# ESP32S31_RADIO register map
Vendor: Espressif; Series: ESP32-S31; File version: 3.52
Registers are 32-bit, read-write, no defined reset value unless marked. A register's access mark holds for its fields unless they carry their own. Offsets are from the block's base; [hi:lo] are bit positions; {n}, {i} and the like mark numbered series; 'fields as' and 'values as' point back to an identical list.

## WIFI_MAC_TXRX_CALLBACKS — Hardware effects of the three HE callbacks between the direct mac_txrx_init prefix and suffix. Diagnostic logging calls are intentionally omitted.
Base 0x2010444C
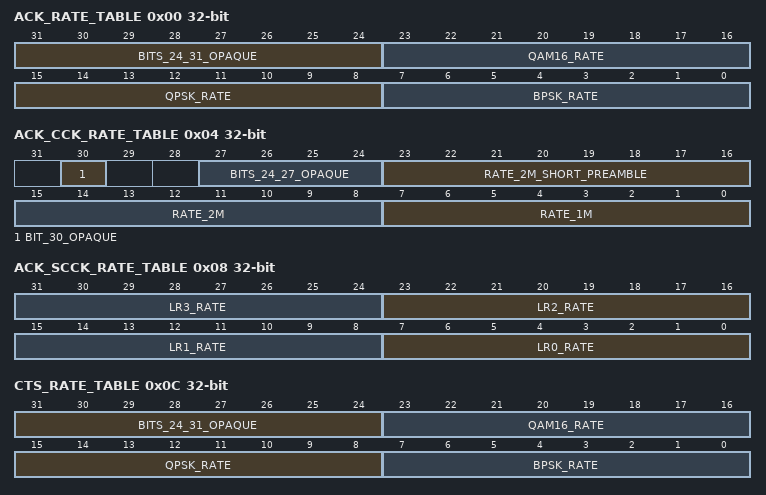
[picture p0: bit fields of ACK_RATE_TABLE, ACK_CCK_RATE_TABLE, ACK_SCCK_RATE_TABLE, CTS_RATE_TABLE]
0x00 ACK_RATE_TABLE — Project-assigned name. ACK_TAB0. hal_he_set_ack_rate(0) publishes 0x00090a0b; complete dbg_read_ack_rate names its three byte lanes.
  [31:24] BITS_24_31_OPAQUE — Opaque: meaning not established.
  [23:16] QAM16_RATE — Project-assigned name.
  [15:8] QPSK_RATE — Project-assigned name.
  [7:0] BPSK_RATE — Project-assigned name.
0x04 ACK_CCK_RATE_TABLE — Project-assigned name. ACK_TAB1. hal_he_set_ack_rate(0) publishes 0x00050100; complete dbg_read_ack_rate names the 1M, 2M and short-preamble 2M lanes.
  [30] BIT_30_OPAQUE — Opaque: meaning not established. Observed source use; the individual hardware meaning is unknown.
  [27:24] BITS_24_27_OPAQUE — Opaque: meaning not established. Observed source use; the individual hardware meaning is unknown.
  [23:16] RATE_2M_SHORT_PREAMBLE — Project-assigned name.
  [15:8] RATE_2M — Project-assigned name.
  [7:0] RATE_1M — Project-assigned name.
0x08 ACK_SCCK_RATE_TABLE — Project-assigned name. ACK_SCCKTAB, decoded by complete dbg_read_ack_rate. The cold setter does not alter this word.
  [8n+7:8n] LR{n}_RATE (n=0..3) — Project-assigned name.
0x0C CTS_RATE_TABLE — Project-assigned name. CTS_TAB0. hal_he_set_ack_rate(0) publishes 0x00090a0b; complete dbg_read_cts_rate names its three byte lanes.
  fields as ACK_RATE_TABLE
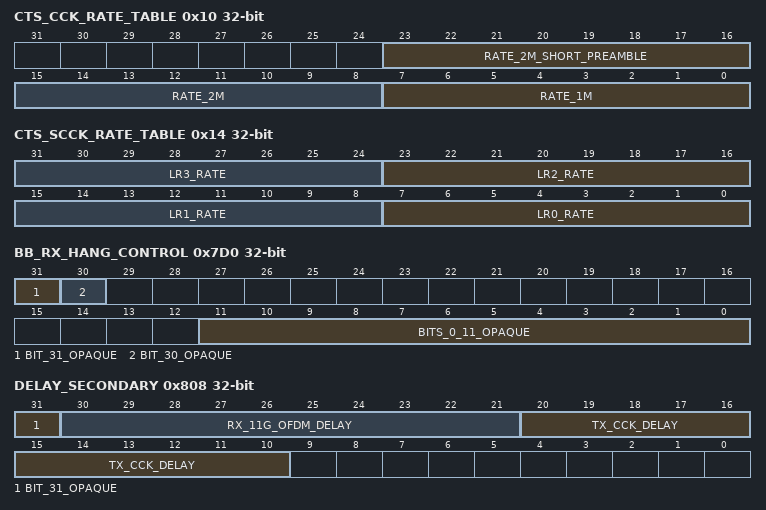
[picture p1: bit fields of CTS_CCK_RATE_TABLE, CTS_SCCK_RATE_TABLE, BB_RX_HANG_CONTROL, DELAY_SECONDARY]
0x10 CTS_CCK_RATE_TABLE — Project-assigned name. CTS_TAB1. hal_he_set_ack_rate(0) publishes 0x00050100; complete dbg_read_cts_rate names the 1M, 2M and short-preamble 2M lanes.
  [23:16] RATE_2M_SHORT_PREAMBLE — Project-assigned name.
  [15:8] RATE_2M — Project-assigned name.
  [7:0] RATE_1M — Project-assigned name.
0x14 CTS_SCCK_RATE_TABLE — Project-assigned name. CTS_SCCKTAB, decoded by complete dbg_read_cts_rate. The cold setter does not alter this word.
  [8n+7:8n] LR{n}_RATE (n=0..3) — Project-assigned name.
0x7D0 BB_RX_HANG_CONTROL — Project-assigned name. Canonical multifunction word. hal_he_set_bbrxhung_time(0) replaces the low twelve bits with 0x00f; the direct mac_txrx_init suffix later sets bits 31 and 30 through two fresh-read RMWs.
  [31] BIT_31_OPAQUE — Opaque: meaning not established.
  [30] BIT_30_OPAQUE — Opaque: meaning not established.
  [11:0] BITS_0_11_OPAQUE — Opaque: meaning not established.
0x808 DELAY_SECONDARY — Project-assigned name. WDEVDELAY1. On-chip hal_he_set_mac_delay uses random slot 0..10 for WDEV_RX_11G_OFDM_DELAY, while complete phy_sifs_reg_init writes 0xea to that field.
  [31] BIT_31_OPAQUE — Opaque: meaning not established. Observed source use; the individual hardware meaning is unknown.
  [30:21] RX_11G_OFDM_DELAY — Project-assigned name.
  [20:10] TX_CCK_DELAY — Project-assigned name.
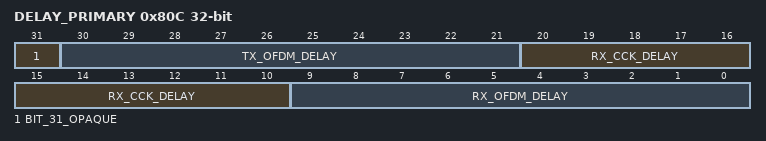
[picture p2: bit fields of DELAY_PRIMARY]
0x80C DELAY_PRIMARY — Project-assigned name. WDEVDELAY. On-chip hal_he_set_mac_delay performs separate RMWs for WDEV_RXCCK_DELAY, WDEV_RXOFDM_DELAY and WDEV_TXOFDM_DELAY; complete phy_sifs_reg_init writes 0x3b8 and 0xf0 to the first two fields.
  [31] BIT_31_OPAQUE — Opaque: meaning not established. Observed source use; the individual hardware meaning is unknown.
  [30:21] TX_OFDM_DELAY — Project-assigned name.
  [20:10] RX_CCK_DELAY — Project-assigned name.
  [9:0] RX_OFDM_DELAY — Project-assigned name.

## WIFI_MAC_TXRX_SUFFIX — Eight Wi-Fi-owned direct fresh-read RMW edges after the three external HE callbacks in complete mac_txrx_init. The ninth edge reaches the independently shared physical word at 0x20104C24 and is modeled by SHARED_RADIO_INIT_CONTROL.
Base 0x20104308
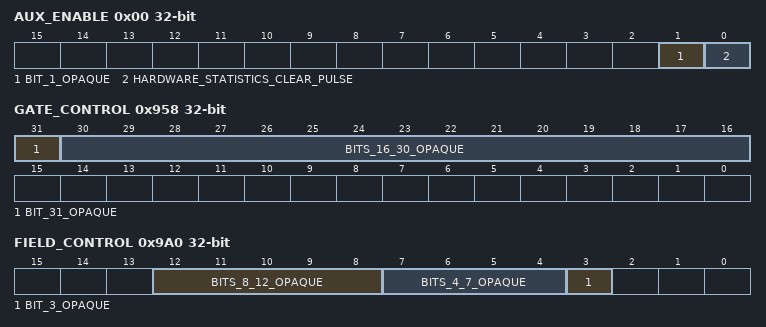
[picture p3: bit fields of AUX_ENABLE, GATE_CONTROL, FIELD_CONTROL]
0x00 AUX_ENABLE — Project-assigned name. The TX/RX init suffix sets bit 1. Complete dbg_clr_hw_count reaches esp_test_clr_hw_statistics, which independently pulses bit 0 high then low while the matching core statistics-clear arm is asserted.
  [1] BIT_1_OPAQUE — Opaque: meaning not established.
  [0] HARDWARE_STATISTICS_CLEAR_PULSE — Project-assigned name. Set and then cleared by complete esp_test_clr_hw_statistics.
0x918 DEFAULT_IMAGE_A — Project-assigned name. Complete suffix replaces the low twelve bits with 0x0f0.
  [11:0] BITS_0_11_OPAQUE — Opaque: meaning not established.
0x958 GATE_CONTROL — Project-assigned name. Complete suffix sets bits 30:16 together, then sets bit 31 through a separate fresh-read edge.
  [31] BIT_31_OPAQUE — Opaque: meaning not established.
  [30:16] BITS_16_30_OPAQUE — Opaque: meaning not established.
0x9A0 FIELD_CONTROL — Project-assigned name. Complete suffix replaces bits 7:4 with four.
  [12:8] BITS_8_12_OPAQUE — Opaque: meaning not established. Observed source use; the individual hardware meaning is unknown.
  [7:4] BITS_4_7_OPAQUE — Opaque: meaning not established.
  [3] BIT_3_OPAQUE — Opaque: meaning not established. Observed source use; the individual hardware meaning is unknown.
